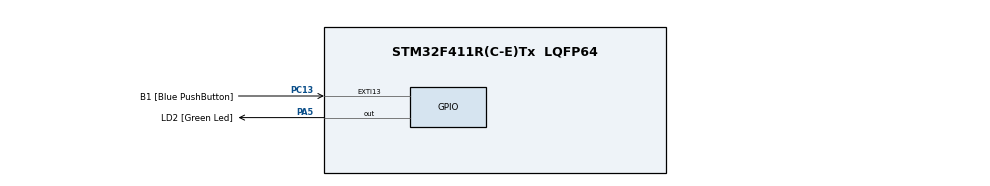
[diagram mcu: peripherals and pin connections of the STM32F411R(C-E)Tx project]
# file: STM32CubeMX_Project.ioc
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FREERTOS.Tasks01=defaultTask,0,128,StartDefaultTask
Mcu.Family=STM32F4
Mcu.Name=STM32F411R(C-E)Tx
Mcu.Package=LQFP64
NVIC.PriorityGroup=NVIC_PRIORITYGROUP_4
PA13.GPIO_Label=TMS
PA13.Mode=Trace-Asynchronous_SW
PA13.Signal=SYS_JTMS-SWDIO
PA14.GPIO_Label=TCK
PA14.Mode=Trace-Asynchronous_SW
PA14.Signal=SYS_JTCK-SWCLK
PA2.GPIO_Label=USART_TX
PA2.Signal=USART2_TX
PA3.GPIO_Label=USART_RX
PA3.Signal=USART2_RX
PA5.GPIO_Label=LD2 [Green Led]
PA5.Signal=GPIO_Output
PB3.GPIO_Label=SWO
PB3.Mode=Trace-Asynchronous_SW
PB3.Signal=SYS_JTDO-SWO
PC13-ANTI_TAMP.GPIO_Label=B1 [Blue PushButton]
PC13-ANTI_TAMP.GPIO_ModeDefaultEXTI=GPIO_MODE_EVT_RISING
PC13-ANTI_TAMP.Signal=GPXTI13
PC14-OSC32_IN.Signal=RCC_OSC32_IN
PC15-OSC32_OUT.Signal=RCC_OSC32_OUT
PH0\ -\ OSC_IN.Signal=RCC_OSC_IN
PH1\ -\ OSC_OUT.Signal=RCC_OSC_OUT
ProjectManager.TargetToolchain=TrueSTUDIO
RCC.48MHZClocksFreq_Value=100000000
RCC.AHBFreq_Value=100000000
RCC.APB1CLKDivider=RCC_HCLK_DIV2
RCC.APB1Freq_Value=50000000
RCC.APB1TimFreq_Value=100000000
RCC.APB2Freq_Value=100000000
RCC.APB2TimFreq_Value=100000000
RCC.CortexFreq_Value=100000000
RCC.FLatency-AdvancedSettings=FLASH_LATENCY_2
RCC.HCLKFreq_Value=100000000
RCC.HSE_VALUE=8000000
RCC.HSI_VALUE=16000000
RCC.LSE_VALUE=32768
RCC.PLLM=8
RCC.PLLN=200
RCC.PLLP=RCC_PLLP_DIV4
RCC.SYSCLKFreq_VALUE=100000000
RCC.SYSCLKSource=RCC_SYSCLKSOURCE_PLLCLK
RCC.VCOOutputFreq_Value=400000000
VP_FREERTOS_VS_ENABLE.Mode=Enabled
board=NUCLEO-F411RE

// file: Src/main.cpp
/**
  ******************************************************************************
  * File Name          : main.c
  * Description        : Main program body
  ******************************************************************************
  *
  * COPYRIGHT(c) 2015 STMicroelectronics
  *
  * Redistribution and use in source and binary forms, with or without modification,
  * are permitted provided that the following conditions are met:
  *   1. Redistributions of source code must retain the above copyright notice,
  *      this list of conditions and the following disclaimer.
  *   2. Redistributions in binary form must reproduce the above copyright notice,
  *      this list of conditions and the following disclaimer in the documentation
  *      and/or other materials provided with the distribution.
  *   3. Neither the name of STMicroelectronics nor the names of its contributors
  *      may be used to endorse or promote products derived from this software
  *      without specific prior written permission.
  *
  * THIS SOFTWARE IS PROVIDED BY THE COPYRIGHT HOLDERS AND CONTRIBUTORS "AS IS"
  * AND ANY EXPRESS OR IMPLIED WARRANTIES, INCLUDING, BUT NOT LIMITED TO, THE
  * IMPLIED WARRANTIES OF MERCHANTABILITY AND FITNESS FOR A PARTICULAR PURPOSE ARE
  * DISCLAIMED. IN NO EVENT SHALL THE COPYRIGHT HOLDER OR CONTRIBUTORS BE LIABLE
  * FOR ANY DIRECT, INDIRECT, INCIDENTAL, SPECIAL, EXEMPLARY, OR CONSEQUENTIAL
  * DAMAGES (INCLUDING, BUT NOT LIMITED TO, PROCUREMENT OF SUBSTITUTE GOODS OR
  * SERVICES; LOSS OF USE, DATA, OR PROFITS; OR BUSINESS INTERRUPTION) HOWEVER
  * CAUSED AND ON ANY THEORY OF LIABILITY, WHETHER IN CONTRACT, STRICT LIABILITY,
  * OR TORT (INCLUDING NEGLIGENCE OR OTHERWISE) ARISING IN ANY WAY OUT OF THE USE
  * OF THIS SOFTWARE, EVEN IF ADVISED OF THE POSSIBILITY OF SUCH DAMAGE.
  *
  ******************************************************************************
  */
#include "config.h"
#include "cmsis_os.h"

osThreadId defaultTaskHandle;

/* USER CODE BEGIN PV */
/* Private variables ---------------------------------------------------------*/
static GPIO_InitTypeDef  GPIO_InitStruct;
/* USER CODE END PV */

void StartDefaultTask(void const * argument);

/* USER CODE BEGIN PFP */
/* Private function prototypes -----------------------------------------------*/

/* USER CODE END PFP */

int main(void)
{

  /* MCU Configuration----------------------------------------------------------*/

  /* Reset of all peripherals, Initializes the Flash interface and the Systick. */
  quadcopter_Init();

  /* Configure the system clock */
  SystemClock_Config();

  /* Initialize all configured peripherals */
  MX_GPIO_Init();

  /* USER CODE BEGIN 2 */
  /*##-1- Enable GPIOA Clock (to be able to program the configuration registers) */
  __GPIOA_CLK_ENABLE();

  /*##-2- Configure PA05 IO in output push-pull mode to drive external LED ###*/
  GPIO_InitStruct.Pin = GPIO_PIN_5;
  GPIO_InitStruct.Mode = GPIO_MODE_OUTPUT_PP;
  GPIO_InitStruct.Pull = GPIO_PULLUP;
  GPIO_InitStruct.Speed = GPIO_SPEED_FAST;
  HAL_GPIO_Init(GPIOA, &GPIO_InitStruct);
  /* USER CODE END 2 */

  /* Create the thread(s) */
  /* definition and creation of defaultTask */
  osThreadDef(defaultTask, StartDefaultTask, osPriorityNormal, 0, 128);
  defaultTaskHandle = osThreadCreate(osThread(defaultTask), NULL);

  /* Start scheduler */
  osKernelStart();

  /* We should never get here as control is now taken by the scheduler */

  /* Infinite loop */
  /* USER CODE BEGIN WHILE */
  while (1)
  {
    HAL_GPIO_TogglePin(GPIOA, GPIO_PIN_5);

    /* Insert delay 100 ms */
    HAL_Delay(100);
  /* USER CODE END WHILE */

  }

}

/* StartDefaultTask function */
void StartDefaultTask(void const * argument)
{

  for(;;)
  {
    osDelay(1);
  }
}

/************************ (C) COPYRIGHT STMicroelectronics *****END OF FILE****/
